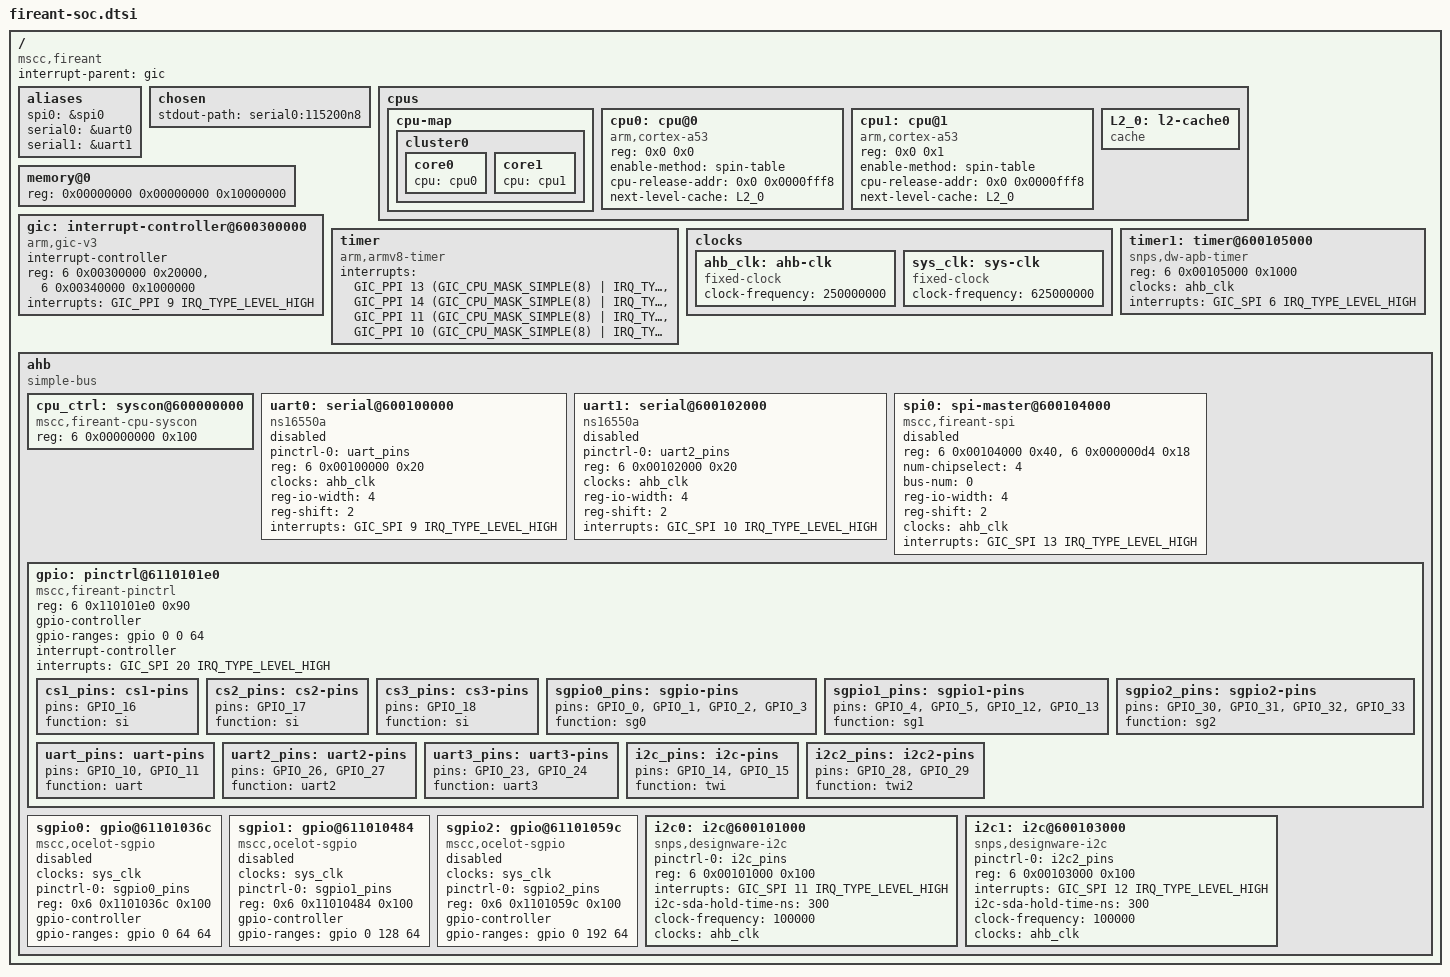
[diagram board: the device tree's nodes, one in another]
// SPDX-License-Identifier: (GPL-2.0+ OR MIT)
/*
 * Copyright (c) 2018 Microsemi Corporation
 */

#include <dt-bindings/gpio/gpio.h>
#include <dt-bindings/interrupt-controller/arm-gic.h>

/ {
	compatible = "mscc,fireant";
	interrupt-parent = <&gic>;
	#address-cells = <2>;
	#size-cells = <1>;

	aliases {
		spi0 = &spi0;
		serial0 = &uart0;
		serial1 = &uart1;
	};

	chosen {
		stdout-path = "serial0:115200n8";
	};

	cpus {
		#address-cells = <2>;
		#size-cells = <0>;
		cpu-map {
			cluster0 {
				core0 {
					cpu = <&cpu0>;
				};
				core1 {
					cpu = <&cpu1>;
				};
			};
		};
		cpu0: cpu@0 {
			compatible = "arm,cortex-a53", "arm,armv8";
			device_type = "cpu";
			reg = <0x0 0x0>;
			enable-method = "spin-table";
			cpu-release-addr = <0x0 0x0000fff8>;
			next-level-cache = <&L2_0>;
		};
		cpu1: cpu@1 {
			compatible = "arm,cortex-a53", "arm,armv8";
			device_type = "cpu";
			reg = <0x0 0x1>;
			enable-method = "spin-table";
			cpu-release-addr = <0x0 0x0000fff8>;
			next-level-cache = <&L2_0>;
		};
		L2_0: l2-cache0 {
			compatible = "cache";
		};
	};

	memory@0 {
		device_type = "memory";
		reg = <0x00000000 0x00000000 0x10000000>;
	};

	gic: interrupt-controller@600300000 {
		compatible = "arm,gic-v3";
		#interrupt-cells = <3>;
		#address-cells = <2>;
		#size-cells = <2>;
		interrupt-controller;
		reg = <6 0x00300000 0x20000>,	/* GICD */
		      <6 0x00340000 0x1000000>;	/* GICR */
		interrupts = <GIC_PPI 9 IRQ_TYPE_LEVEL_HIGH>;
	};

	timer {
		compatible = "arm,armv8-timer";
		interrupts = <GIC_PPI 13 (GIC_CPU_MASK_SIMPLE(8) | IRQ_TYPE_LEVEL_LOW)>,
			     <GIC_PPI 14 (GIC_CPU_MASK_SIMPLE(8) | IRQ_TYPE_LEVEL_LOW)>,
			     <GIC_PPI 11 (GIC_CPU_MASK_SIMPLE(8) | IRQ_TYPE_LEVEL_LOW)>,
			     <GIC_PPI 10 (GIC_CPU_MASK_SIMPLE(8) | IRQ_TYPE_LEVEL_LOW)>;
	};

	clocks: clocks {
		ahb_clk: ahb-clk {
			compatible = "fixed-clock";
			#clock-cells = <0>;
			clock-frequency = <250000000>;
		};
		sys_clk: sys-clk {
			compatible = "fixed-clock";
			#clock-cells = <0>;
			clock-frequency = <625000000>;
		};
	};

	timer1: timer@600105000 {
		compatible = "snps,dw-apb-timer";
		reg = <6 0x00105000 0x1000>;
		clocks = <&ahb_clk>;
		clock-names = "timer";
		interrupts = <GIC_SPI 6 IRQ_TYPE_LEVEL_HIGH>;
	};

	ahb {
		compatible = "simple-bus";
		#address-cells = <2>;
		#size-cells = <1>;
		ranges;

		cpu_ctrl: syscon@600000000 {
			compatible = "mscc,fireant-cpu-syscon", "syscon";
			reg = <6 0x00000000 0x100>;
		};

		uart0: serial@600100000 {
			pinctrl-0 = <&uart_pins>;
			pinctrl-names = "default";
			compatible = "ns16550a";
			reg = <6 0x00100000 0x20>;
			clocks = <&ahb_clk>;
			reg-io-width = <4>;
			reg-shift = <2>;
			interrupts = <GIC_SPI 9 IRQ_TYPE_LEVEL_HIGH>;

			status = "disabled";
		};

		uart1: serial@600102000 {
			pinctrl-0 = <&uart2_pins>;
			pinctrl-names = "default";
			compatible = "ns16550a";
			reg = <6 0x00102000 0x20>;
			clocks = <&ahb_clk>;
			reg-io-width = <4>;
			reg-shift = <2>;
			interrupts = <GIC_SPI 10 IRQ_TYPE_LEVEL_HIGH>;

			status = "disabled";
		};

		spi0: spi-master@600104000 {
			#address-cells = <1>;
			#size-cells = <0>;
			compatible = "mscc,fireant-spi", "snps,dw-apb-ssi";
			reg = <6 0x00104000 0x40>, <6 0x000000d4 0x18>;
			num-chipselect = <4>;
			bus-num = <0>;
			reg-io-width = <4>;
			reg-shift = <2>;
			clocks = <&ahb_clk>;
			interrupts = <GIC_SPI 13 IRQ_TYPE_LEVEL_HIGH>;

			status = "disabled";
		};

		gpio: pinctrl@6110101e0 {
			compatible = "mscc,fireant-pinctrl";
			reg = <6 0x110101e0 0x90>;
			gpio-controller;
			#gpio-cells = <2>;
			gpio-ranges = <&gpio 0 0 64>;
                        interrupt-controller;
			interrupts = <GIC_SPI 20 IRQ_TYPE_LEVEL_HIGH>;
			#interrupt-cells = <2>;

			cs1_pins: cs1-pins {
				pins = "GPIO_16";
				function = "si";
			};

			cs2_pins: cs2-pins {
				pins = "GPIO_17";
				function = "si";
			};

			cs3_pins: cs3-pins {
				pins = "GPIO_18";
				function = "si";
			};

			sgpio0_pins: sgpio-pins {
				pins = "GPIO_0", "GPIO_1", "GPIO_2", "GPIO_3";
				function = "sg0";
			};

			sgpio1_pins: sgpio1-pins {
				pins = "GPIO_4", "GPIO_5", "GPIO_12", "GPIO_13";
				function = "sg1";
			};

			sgpio2_pins: sgpio2-pins {
				pins = "GPIO_30", "GPIO_31", "GPIO_32", "GPIO_33";
				function = "sg2";
			};

			uart_pins: uart-pins {
				pins = "GPIO_10", "GPIO_11";
				function = "uart";
			};

			uart2_pins: uart2-pins {
				pins = "GPIO_26", "GPIO_27";
				function = "uart2";
			};

			uart3_pins: uart3-pins {
				pins = "GPIO_23", "GPIO_24";
				function = "uart3";
			};

			i2c_pins: i2c-pins {
				pins = "GPIO_14", "GPIO_15";
				function = "twi";
			};

			i2c2_pins: i2c2-pins {
				pins = "GPIO_28", "GPIO_29";
				function = "twi2";
			};
		};

		sgpio0: gpio@61101036c {
			compatible = "mscc,ocelot-sgpio";
			status = "disabled";
			clocks = <&sys_clk>;
			pinctrl-0 = <&sgpio0_pins>;
			pinctrl-names = "default";
			reg = <0x6 0x1101036c 0x100>;
			gpio-controller;
			#gpio-cells = <2>;
			gpio-ranges = <&gpio 0 64 64>;
		};

		sgpio1: gpio@611010484 {
			compatible = "mscc,ocelot-sgpio";
			status = "disabled";
			clocks = <&sys_clk>;
			pinctrl-0 = <&sgpio1_pins>;
			pinctrl-names = "default";
			reg = <0x6 0x11010484 0x100>;
			gpio-controller;
			#gpio-cells = <2>;
			gpio-ranges = <&gpio 0 128 64>;
		};

		sgpio2: gpio@61101059c {
			compatible = "mscc,ocelot-sgpio";
			status = "disabled";
			clocks = <&sys_clk>;
			pinctrl-0 = <&sgpio2_pins>;
			pinctrl-names = "default";
			reg = <0x6 0x1101059c 0x100>;
			gpio-controller;
			#gpio-cells = <2>;
			gpio-ranges = <&gpio 0 192 64>;
		};

		i2c0: i2c@600101000 {
			compatible = "snps,designware-i2c";
			pinctrl-0 = <&i2c_pins>;
			pinctrl-names = "default";
			reg = <6 0x00101000 0x100>;
			#address-cells = <1>;
			#size-cells = <0>;
			interrupts = <GIC_SPI 11 IRQ_TYPE_LEVEL_HIGH>;
			i2c-sda-hold-time-ns = <300>;
			clock-frequency = <100000>;
			clocks = <&ahb_clk>;
		};

		i2c1: i2c@600103000 {
			compatible = "snps,designware-i2c";
			pinctrl-0 = <&i2c2_pins>;
			pinctrl-names = "default";
			reg = <6 0x00103000 0x100>;
			#address-cells = <1>;
			#size-cells = <0>;
			interrupts = <GIC_SPI 12 IRQ_TYPE_LEVEL_HIGH>;
			i2c-sda-hold-time-ns = <300>;
			clock-frequency = <100000>;
			clocks = <&ahb_clk>;
		};
	};
};
